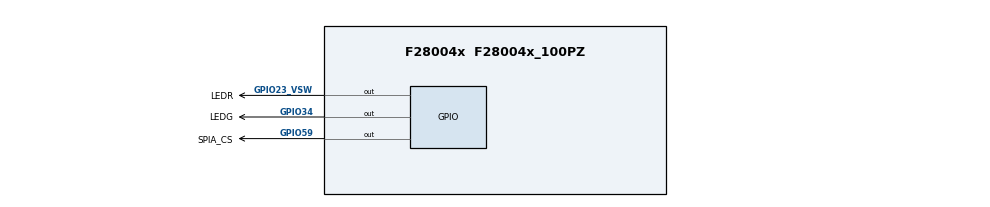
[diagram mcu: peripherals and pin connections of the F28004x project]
/**
 * @cliArgs --device "F28004x" --part "F28004x_100PZ" --package "F28004x_100PZ" --context "system" --product "C2000WARE@5.03.00.00"
 * @versions {"tool":"1.21.0+3721"}
 */

/**
 * Import the modules used in this configuration.
 */
const adc            = scripting.addModule("/driverlib/adc.js", {}, false);
const adc1           = adc.addInstance();
const adc2           = adc.addInstance();
const adc3           = adc.addInstance();
const cla            = scripting.addModule("/driverlib/cla.js", {}, false);
const cla1           = cla.addInstance();
const device_support = scripting.addModule("/driverlib/device_support.js");
const epwm           = scripting.addModule("/driverlib/epwm.js", {}, false);
const epwm1          = epwm.addInstance();
const epwm2          = epwm.addInstance();
const epwm3          = epwm.addInstance();
const gpio           = scripting.addModule("/driverlib/gpio.js", {}, false);
const gpio1          = gpio.addInstance();
const gpio2          = gpio.addInstance();
const gpio3          = gpio.addInstance();
const i2c            = scripting.addModule("/driverlib/i2c.js", {}, false);
const i2c1           = i2c.addInstance();
const memcfg         = scripting.addModule("/driverlib/memcfg.js");
const spi            = scripting.addModule("/driverlib/spi.js", {}, false);
const spi1           = spi.addInstance();

/**
 * Write custom configuration values to the imported modules.
 */
adc1.adcClockPrescaler       = "ADC_CLK_DIV_2_0";
adc1.socHighPriorityMode     = "ADC_PRI_THRU_SOC2_HIPRI";
adc1.enabledSOCs             = ["ADC_SOC_NUMBER0","ADC_SOC_NUMBER1","ADC_SOC_NUMBER2"];
adc1.soc0Name                = "MOTOR_IW";
adc1.soc0Channel             = "ADC_CH_ADCIN9";
adc1.soc0Trigger             = "ADC_TRIGGER_EPWM1_SOCA";
adc1.soc0SampleWindow        = 8;
adc1.soc1Name                = "MOTOR_VW";
adc1.soc1IndependentNameMode = true;
adc1.soc0IndependentNameMode = true;
adc1.soc1Trigger             = "ADC_TRIGGER_EPWM1_SOCA";
adc1.soc1SampleWindow        = 8;
adc1.soc1Channel             = "ADC_CH_ADCIN10";
adc1.soc2SampleWindow        = 8;
adc1.soc2Name                = "MOTOR_VDC";
adc1.soc2IndependentNameMode = true;
adc1.soc2Channel             = "ADC_CH_ADCIN5";
adc1.soc2Trigger             = "ADC_TRIGGER_EPWM1_SOCA";
adc1.soc2InterruptTrigger    = "ADC_INT_SOC_TRIGGER_ADCINT1";
adc1.$name                   = "ADC_A";

adc2.adcBase                 = "ADCB_BASE";
adc2.adcClockPrescaler       = "ADC_CLK_DIV_2_0";
adc2.socHighPriorityMode     = "ADC_PRI_THRU_SOC2_HIPRI";
adc2.enabledSOCs             = ["ADC_SOC_NUMBER0","ADC_SOC_NUMBER1","ADC_SOC_NUMBER2"];
adc2.soc0Name                = "MOTOR_IU";
adc2.soc0Channel             = "ADC_CH_ADCIN2";
adc2.soc0IndependentNameMode = true;
adc2.soc0SampleWindow        = 8;
adc2.soc0Trigger             = "ADC_TRIGGER_EPWM1_SOCA";
adc2.soc1Name                = "MOTOR_VU";
adc2.soc1IndependentNameMode = true;
adc2.soc1Trigger             = "ADC_TRIGGER_EPWM1_SOCA";
adc2.soc1SampleWindow        = 8;
adc2.soc2Name                = "MOTOR_TC";
adc2.soc2IndependentNameMode = true;
adc2.soc2Channel             = "ADC_CH_ADCIN3";
adc2.soc2Trigger             = "ADC_TRIGGER_EPWM1_SOCA";
adc2.soc2SampleWindow        = 8;
adc2.$name                   = "ADC_B";

adc3.adcBase                 = "ADCC_BASE";
adc3.adcClockPrescaler       = "ADC_CLK_DIV_2_0";
adc3.socHighPriorityMode     = "ADC_PRI_THRU_SOC1_HIPRI";
adc3.enabledSOCs             = ["ADC_SOC_NUMBER0","ADC_SOC_NUMBER1"];
adc3.soc0Name                = "MOTOR_IV";
adc3.soc0IndependentNameMode = true;
adc3.soc0Trigger             = "ADC_TRIGGER_EPWM1_SOCA";
adc3.soc0SampleWindow        = 8;
adc3.soc1Channel             = "ADC_CH_ADCIN2";
adc3.soc1Name                = "MOTOR_VV";
adc3.soc1IndependentNameMode = true;
adc3.soc1Trigger             = "ADC_TRIGGER_EPWM1_SOCA";
adc3.soc1SampleWindow        = 8;
adc3.$name                   = "ADC_C";

cla1.enable_CLA_TASK_2                     = false;
cla1.enable_CLA_TASK_4                     = false;
cla1.enable_CLA_TASK_5                     = false;
cla1.enable_CLA_TASK_6                     = false;
cla1.enable_CLA_TASK_7                     = false;
cla1.enable_CLA_TASK_8                     = false;
cla1.enable_CLA_TASK_3                     = false;
cla1.name_CLA_TASK_1                       = "CLATaskCallback1";
cla1.cpuint_CLA_TASK_2                     = false;
cla1.cpuint_CLA_TASK_3                     = false;
cla1.cpuint_CLA_TASK_5                     = false;
cla1.cpuint_CLA_TASK_4                     = false;
cla1.cpuint_CLA_TASK_6                     = false;
cla1.cpuint_CLA_TASK_7                     = false;
cla1.cpuint_CLA_TASK_8                     = false;
cla1.$name                                 = "myCLA1";
cla1.intconfig_CLA_TASK_1.interruptHandler = "cla1Isr1";

epwm1.$name                                                      = "EPWMU";
epwm1.epwmTimebase_hsClockDiv                                    = "EPWM_HSCLOCK_DIVIDER_1";
epwm1.epwmTimebase_period                                        = 5000;
epwm1.epwmTimebase_counterMode                                   = "EPWM_COUNTER_MODE_UP_DOWN";
epwm1.epwmTimebase_counterModeAfterSync                          = "EPWM_COUNT_MODE_UP_AFTER_SYNC";
epwm1.epwmTimebase_phaseEnable                                   = true;
epwm1.epwmTimebase_syncOutPulseMode                              = "EPWM_SYNC_OUT_PULSE_ON_COUNTER_ZERO";
epwm1.epwmCounterCompare_cmpA                                    = 2500;
epwm1.epwmCounterCompare_shadowLoadModeCMPA                      = "EPWM_COMP_LOAD_ON_CNTR_ZERO_PERIOD";
epwm1.epwmActionQualifier_EPWM_AQ_OUTPUT_A_ON_TIMEBASE_UP_CMPA   = "EPWM_AQ_OUTPUT_LOW";
epwm1.epwmActionQualifier_EPWM_AQ_OUTPUT_A_ON_TIMEBASE_DOWN_CMPA = "EPWM_AQ_OUTPUT_HIGH";
epwm1.epwmDeadband_delayRED                                      = 200;
epwm1.epwmDeadband_delayFED                                      = 200;
epwm1.epwmEventTrigger_enableInterrupt                           = true;
epwm1.epwmEventTrigger_EPWM_SOC_A_triggerEnable                  = true;
epwm1.epwmEventTrigger_EPWM_SOC_A_triggerEventPrescalar          = "1";

epwm2.$name                                                      = "EPWMV";
epwm2.copyUse                                                    = true;
epwm2.copyFrom                                                   = "EPWMU";
epwm2.epwmTimebase_hsClockDiv                                    = "EPWM_HSCLOCK_DIVIDER_1";
epwm2.epwmTimebase_period                                        = 5000;
epwm2.epwmTimebase_counterMode                                   = "EPWM_COUNTER_MODE_UP_DOWN";
epwm2.epwmTimebase_counterModeAfterSync                          = "EPWM_COUNT_MODE_UP_AFTER_SYNC";
epwm2.epwmTimebase_phaseEnable                                   = true;
epwm2.epwmTimebase_syncOutPulseMode                              = "EPWM_SYNC_OUT_PULSE_ON_COUNTER_ZERO";
epwm2.epwmCounterCompare_cmpA                                    = 2500;
epwm2.epwmCounterCompare_shadowLoadModeCMPA                      = "EPWM_COMP_LOAD_ON_CNTR_ZERO_PERIOD";
epwm2.epwmActionQualifier_EPWM_AQ_OUTPUT_A_ON_TIMEBASE_UP_CMPA   = "EPWM_AQ_OUTPUT_LOW";
epwm2.epwmActionQualifier_EPWM_AQ_OUTPUT_A_ON_TIMEBASE_DOWN_CMPA = "EPWM_AQ_OUTPUT_HIGH";
epwm2.epwmDeadband_delayRED                                      = 200;
epwm2.epwmDeadband_delayFED                                      = 200;
epwm2.epwmEventTrigger_enableInterrupt                           = false;
epwm2.epwmEventTrigger_EPWM_SOC_A_triggerEnable                  = false;

epwm3.$name                                                      = "EPWMW";
epwm3.copyUse                                                    = true;
epwm3.copyFrom                                                   = "EPWMU";
epwm3.epwmTimebase_hsClockDiv                                    = "EPWM_HSCLOCK_DIVIDER_1";
epwm3.epwmTimebase_period                                        = 5000;
epwm3.epwmTimebase_counterMode                                   = "EPWM_COUNTER_MODE_UP_DOWN";
epwm3.epwmTimebase_counterModeAfterSync                          = "EPWM_COUNT_MODE_UP_AFTER_SYNC";
epwm3.epwmTimebase_phaseEnable                                   = true;
epwm3.epwmTimebase_syncOutPulseMode                              = "EPWM_SYNC_OUT_PULSE_ON_COUNTER_ZERO";
epwm3.epwmCounterCompare_cmpA                                    = 2500;
epwm3.epwmCounterCompare_shadowLoadModeCMPA                      = "EPWM_COMP_LOAD_ON_CNTR_ZERO_PERIOD";
epwm3.epwmActionQualifier_EPWM_AQ_OUTPUT_A_ON_TIMEBASE_UP_CMPA   = "EPWM_AQ_OUTPUT_LOW";
epwm3.epwmActionQualifier_EPWM_AQ_OUTPUT_A_ON_TIMEBASE_DOWN_CMPA = "EPWM_AQ_OUTPUT_HIGH";
epwm3.epwmDeadband_delayRED                                      = 200;
epwm3.epwmDeadband_delayFED                                      = 200;
epwm3.epwmEventTrigger_enableInterrupt                           = false;
epwm3.epwmEventTrigger_EPWM_SOC_A_triggerEnable                  = false;

gpio1.$name           = "LEDR";
gpio1.direction       = "GPIO_DIR_MODE_OUT";
gpio1.gpioPin.$assign = "GPIO23_VSW";

gpio2.$name           = "LEDG";
gpio2.direction       = "GPIO_DIR_MODE_OUT";
gpio2.gpioPin.$assign = "GPIO34";

gpio3.$name           = "SPIA_CS";
gpio3.gpioPin.$assign = "GPIO59";

i2c1.$name = "myI2C0";

memcfg.config_MEMCFG_SECT_LS1        = "CLA_data";
memcfg.init_MEMCFG_SECT_MSGCPUTOCLA1 = true;
memcfg.init_MEMCFG_SECT_MSGCLA1TOCPU = true;
memcfg.config_MEMCFG_SECT_LS2        = "CLA_data";
memcfg.config_MEMCFG_SECT_LS3        = "CLA_data";
memcfg.config_MEMCFG_SECT_LS0        = "CLA_prog";

spi1.dataWidth        = "8";
spi1.mode             = "SPI_MODE_CONTROLLER";
spi1.$name            = "SPI0";
spi1.emulationMode    = "SPI_EMULATION_FREE_RUN";
spi1.transferProtocol = "SPI_PROT_POL1PHA0";
spi1.bitRate          = 7000000;
spi1.picoQual.$name   = "myGPIOQUAL0";
spi1.pociQual.$name   = "myGPIOQUAL1";
spi1.clkQual.$name    = "myGPIOQUAL2";
spi1.pteQual.$name    = "myGPIOQUAL3";

/**
 * Pinmux solution for unlocked pins/peripherals. This ensures that minor changes to the automatic solver in a future
 * version of the tool will not impact the pinmux you originally saw.  These lines can be completely deleted in order to
 * re-solve from scratch.
 */
epwm1.epwm.$suggestSolution           = "EPWM3";
epwm1.epwm.epwm_aPin.$suggestSolution = "GPIO4";
epwm1.epwm.epwm_bPin.$suggestSolution = "GPIO5";
epwm2.epwm.$suggestSolution           = "EPWM2";
epwm2.epwm.epwm_aPin.$suggestSolution = "GPIO2";
epwm2.epwm.epwm_bPin.$suggestSolution = "GPIO3";
epwm3.epwm.$suggestSolution           = "EPWM1";
epwm3.epwm.epwm_aPin.$suggestSolution = "GPIO0";
epwm3.epwm.epwm_bPin.$suggestSolution = "GPIO1";
i2c1.i2c.$suggestSolution             = "I2CA";
i2c1.i2c.i2c_sdaPin.$suggestSolution  = "GPIO26";
i2c1.i2c.i2c_sclPin.$suggestSolution  = "GPIO27";
spi1.spi.$suggestSolution             = "SPIA";
spi1.spi.spi_picoPin.$suggestSolution = "GPIO16";
spi1.spi.spi_pociPin.$suggestSolution = "GPIO10";
spi1.spi.spi_clkPin.$suggestSolution  = "GPIO18_X2";
spi1.spi.spi_ptePin.$suggestSolution  = "GPIO11";
